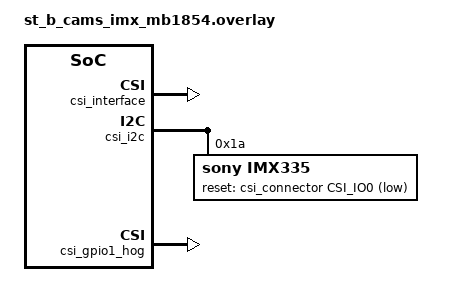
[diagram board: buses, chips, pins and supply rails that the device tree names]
/*
 * Copyright (c) 2025 STMicroelectronics.
 *
 * SPDX-License-Identifier: Apache-2.0
 *
 */

#include <zephyr/dt-bindings/gpio/raspberrypi-csi-connector.h>
#include <zephyr/dt-bindings/video/video-interfaces.h>

/ {
	chosen {
		zephyr,camera = &pipe_main;
	};

	imx335_input_clock: imx335-input-clock {
		compatible = "fixed-clock";
		clock-frequency = <24000000>;
		#clock-cells = <0>;
	};
};

&csi_interface {
	status = "okay";
};

&csi_ep_in {
	remote-endpoint-label = "imx335_ep_out";
	bus-type = <VIDEO_BUS_TYPE_CSI2_DPHY>;
	data-lanes = <1 2>;
};

&csi_i2c {
	imx335: camera@1a {
		compatible = "sony,imx335";
		clocks = <&imx335_input_clock>;
		reg = <0x1a>;
		reset-gpios = <&csi_connector CSI_IO0 GPIO_ACTIVE_LOW>;

		port {
			imx335_ep_out: endpoint {
				remote-endpoint-label = "csi_ep_in";
				bus-type = <VIDEO_BUS_TYPE_CSI2_DPHY>;
				data-lanes = <1 2>;
			};
		};
	};
};

/* Power the camera module */
&csi_gpio1_hog {
	status = "okay";
	output-high;
};
